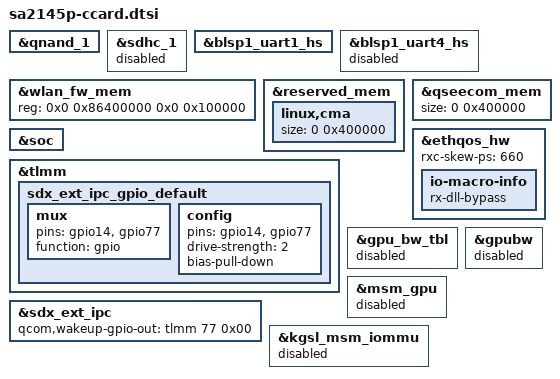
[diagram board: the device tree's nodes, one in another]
/* Copyright (c) 2020, The Linux Foundation. All rights reserved.
 *
 * This program is free software; you can redistribute it and/or modify
 * it under the terms of the GNU General Public License version 2 and
 * only version 2 as published by the Free Software Foundation.
 *
 * This program is distributed in the hope that it will be useful,
 * but WITHOUT ANY WARRANTY; without even the implied warranty of
 * MERCHANTABILITY or FITNESS FOR A PARTICULAR PURPOSE.  See the
 * GNU General Public License for more details.
 */

&qnand_1 {
	status = "okay";
};

&sdhc_1 {
	status = "disabled";
};

&blsp1_uart1_hs {
	status = "ok";
};

&blsp1_uart4_hs {
	status = "disabled";
};

&wlan_fw_mem {
	reg = <0x0 0x86400000 0x0 0x100000>;
};

&reserved_mem {
	linux,cma {
		size = <0 0x400000>;
	};
};

&qseecom_mem {
	size = <0 0x400000>;
};

&soc {
	/delete-node/ qcom,wlan_dsp@7000000;
	/delete-node/ qcom,icnss@18800000;
};

&reserved_mem {
	/delete-node/ wlan_msa_region@88E0000;
	/delete-node/ wlan_fw_mem@86400000;
};

&tlmm {
	sdx_ext_ipc_gpio_default: sdx_ext_ipc_gpio_default {
		mux {
			pins = "gpio14", "gpio77";
			function = "gpio";
		};

		config {
			pins = "gpio14", "gpio77";
			drive-strength = <2>;
			bias-pull-down;
		};
	};
};

&sdx_ext_ipc {
	qcom,wakeup-gpio-out = <&tlmm 77 0x00>;
};

&tlmm {
	/delete-node/ mdss_hdmi_ddc_active;
	/delete-node/ mdss_hdmi_ddc_suspend;
};

&ethqos_hw {
	pinctrl-names = "dev-emac-mdc", "dev-emac-mdio",
		"dev-emac-rgmii_txd0_state", "dev-emac-rgmii_txd1_state",
		"dev-emac-rgmii_txd2_state", "dev-emac-rgmii_txd3_state",
		"dev-emac-rgmii_txc_state",  "dev-emac-rgmii_tx_ctl_state",
		"dev-emac-rgmii_rxd0_state", "dev-emac-rgmii_rxd1_state",
		"dev-emac-rgmii_rxd2_state", "dev-emac-rgmii_rxd3_state",
		"dev-emac-rgmii_rxc_state", "dev-emac-rgmii_rx_ctl_state",
		"dev-emac-phy_intr", "dev-emac-phy_reset_state";

	rxc-skew-ps = <660>;
	io-macro-info {
		/delete-property/ sdcc-usr-ctl;
		rx-dll-bypass;
	};
};

&gpu_bw_tbl {
	status = "disabled";
};

&gpubw {
	status = "disabled";
};

&msm_gpu {
	status = "disabled";
};

&kgsl_msm_iommu {
	status = "disabled";
};
